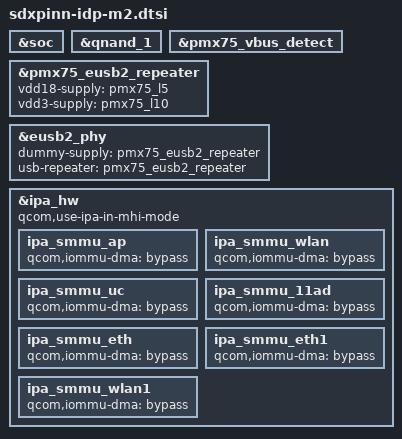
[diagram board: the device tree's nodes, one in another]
#include "sdxpinn-pmic-overlay.dtsi"

&soc {
};

&qnand_1 {
	status = "ok";
};

&pmx75_vbus_detect {
	status = "ok";
};

&pmx75_eusb2_repeater {
	vdd18-supply = <&pmx75_l5>;
	vdd3-supply = <&pmx75_l10>;
	status = "ok";
};

&eusb2_phy {
	dummy-supply = <&pmx75_eusb2_repeater>;
	usb-repeater = <&pmx75_eusb2_repeater>;
};

&ipa_hw {
	qcom,use-ipa-in-mhi-mode;
	ipa_smmu_ap {
		qcom,iommu-dma = "bypass";
	};

	ipa_smmu_wlan {
		qcom,iommu-dma = "bypass";
	};

	ipa_smmu_uc {
		qcom,iommu-dma = "bypass";
	};

	ipa_smmu_11ad {
		qcom,iommu-dma = "bypass";
	};

	ipa_smmu_eth {
		qcom,iommu-dma = "bypass";
	};

	ipa_smmu_eth1 {
		qcom,iommu-dma = "bypass";
	};

	ipa_smmu_wlan1 {
		qcom,iommu-dma = "bypass";
	};

};
